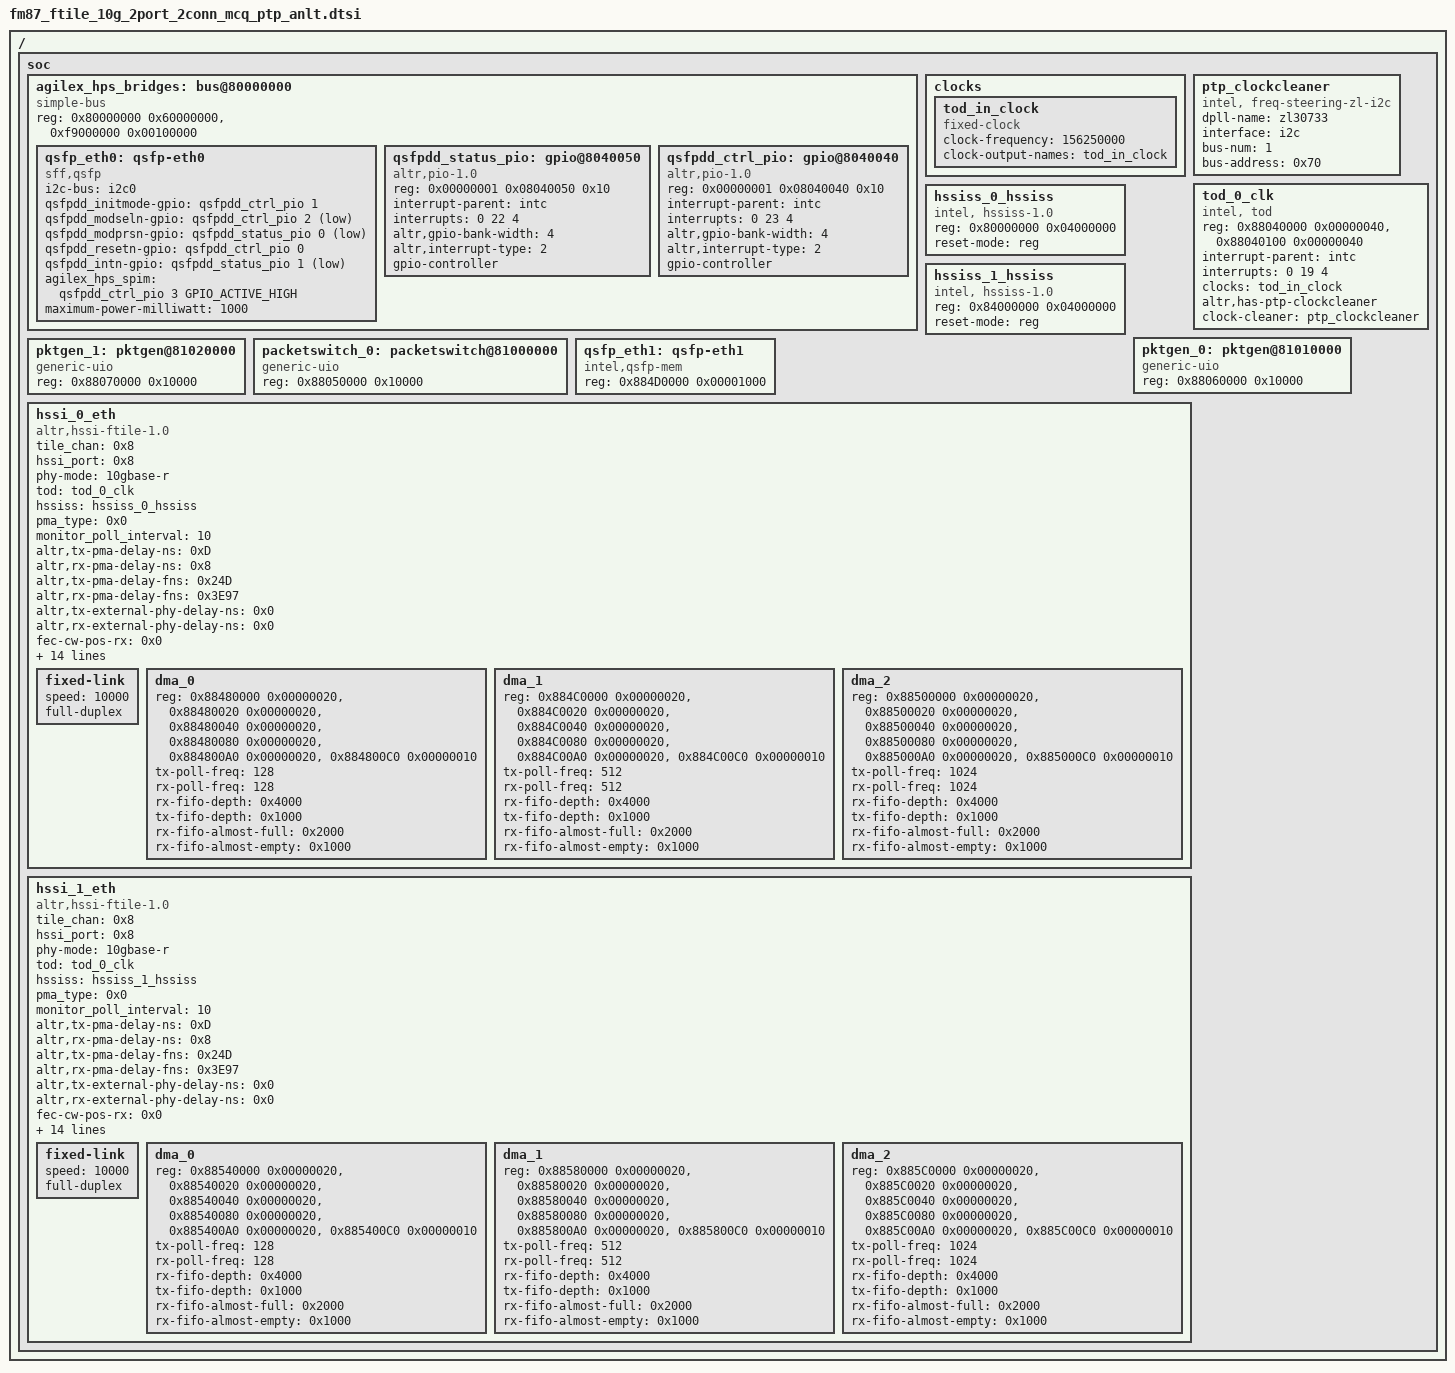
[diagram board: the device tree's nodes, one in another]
// SPDX-License-Identifier: GPL-2.0
/*
 * Copyright(C) 2024, Altera Corporation
 */

/* Add this piece of dtsi fragment as #include "fm87_ftile_25g_ptp.dtsi"
 * in the file socfpga_fm87_ftile_25g_ptp.dts. Compile it in the kernel along with
 * socfpga_agilex.dtsi
 */

/{
	soc {
		agilex_hps_bridges: bus@80000000 {
			compatible = "simple-bus";
			reg = <0x80000000 0x60000000>,
				  <0xf9000000 0x00100000>;
			reg-names = "axi_h2f", "axi_h2f_lw";
			#address-cells = <2>;
			#size-cells = <1>;
			ranges =   <0x00000000 0x00000000 0xf9000000 0x00001000>,
				   <0x00000001 0x00000000 0x80000000 0x04000000>,
				   <0x00000001 0x00000000 0x84000000 0x04000000>,
				   <0x00000001 0x00000000 0x88040000 0x00000040>,
				   <0x00000001 0x00000000 0x88040100 0x00000140>,
				   <0x00000001 0x08040050 0x88040050 0x00000010>,
				   <0x00000001 0x08040040 0x88040040 0x00000010>,
				   <0x00000001 0x00000000 0x88050000 0x00010000>,
				   <0x00000001 0x00000000 0x88060000 0x00010000>,
				   <0x00000001 0x00000000 0x88070000 0x00010000>,
				   <0x00000001 0x00000000 0x88480000 0x00000100>,
				   <0x00000001 0x00000000 0x884C0000 0x00000100>,
				   <0x00000001 0x00000000 0x88500000 0x00000100>,
				   <0x00000001 0x00000000 0x88540000 0x00000100>,
				   <0x00000001 0x00000000 0x88580000 0x00000100>,
				   <0x00000001 0x00000000 0x885C0000 0x00000100>,
				   <0x00000001 0x00000000 0x884D0000 0x00001000>;

			qsfp_eth0: qsfp-eth0 {
				compatible = "sff,qsfp";
				i2c-bus = <&i2c0>;
				qsfpdd_initmode-gpio = <&qsfpdd_ctrl_pio 1 GPIO_ACTIVE_HIGH>;
				qsfpdd_modseln-gpio = <&qsfpdd_ctrl_pio 2 GPIO_ACTIVE_LOW>;
				qsfpdd_modprsn-gpio = <&qsfpdd_status_pio 0 GPIO_ACTIVE_LOW>;
				qsfpdd_resetn-gpio = <&qsfpdd_ctrl_pio 0 GPIO_ACTIVE_HIGH>;
				qsfpdd_intn-gpio = <&qsfpdd_status_pio 1 GPIO_ACTIVE_LOW>;
				agilex_hps_spim = <&qsfpdd_ctrl_pio 3 GPIO_ACTIVE_HIGH>;
				maximum-power-milliwatt = <1000>;
				status = "okay";
			};

			qsfpdd_status_pio: gpio@8040050 {
				compatible = "altr,pio-1.0";
				reg = <0x00000001 0x08040050 0x10>;
				interrupt-parent = <&intc>;
				interrupts = <0 22 4>;
				altr,gpio-bank-width = <4>;
				altr,interrupt-type = <2>;
				#gpio-cells = <2>;
				gpio-controller;
				status = "okay";
			};

			qsfpdd_ctrl_pio: gpio@8040040 {
				compatible = "altr,pio-1.0";
				reg = <0x00000001 0x08040040 0x10>;
				interrupt-parent = <&intc>;
				interrupts = <0 23 4>;
				altr,gpio-bank-width = <4>;
				altr,interrupt-type = <2>;
				#gpio-cells = <2>;
				gpio-controller;
				status = "okay";
			};
		};
		clocks {
			tod_in_clock: tod_in_clock {
				#clock-cells = <0>;
				compatible = "fixed-clock";
				clock-frequency = <156250000>;
				clock-output-names = "tod_in_clock";
			};
		};

		ptp_clockcleaner: ptp_clockcleaner {
			compatible = "intel, freq-steering-zl-i2c";
			dpll-name = "zl30733";
			interface  = "i2c";
			bus-num    = <1>;
			bus-address = <0x70>;
		};

		tod_0_clk: tod_0_clk {
			compatible = "intel, tod";
			reg-names =	"tod_ctrl",
					"pps_ctrl";
			reg = <0x88040000 0x00000040>,
				  <0x88040100 0x00000040>;
			interrupt-parent = <&intc>;
			interrupt-names = "pps_irq";
			interrupts = <0 19 4>;
			clocks = <&tod_in_clock>;
			clock-names = "tod_clock";
			status = "okay";
			altr,has-ptp-clockcleaner;
			clock-cleaner = <&ptp_clockcleaner>;
		};

		hssiss_0_hssiss: hssiss_0_hssiss {
			compatible = "intel, hssiss-1.0";
			reg-names = "sscsr";
			reg = <0x80000000 0x04000000>;
			reset-mode ="reg";
		};
		hssiss_1_hssiss: hssiss_1_hssiss {
			compatible = "intel, hssiss-1.0";
			reg-names = "sscsr";
			reg = <0x84000000 0x04000000>;
			reset-mode ="reg";
		};
		pktgen_0: pktgen@81010000 {
			compatible = "generic-uio";
			reg = <0x88060000 0x10000>;
			reg-names = "pkt_cli";
		};
		pktgen_1: pktgen@81020000 {
			compatible = "generic-uio";
			reg = <0x88070000 0x10000>;
			reg-names = "pkt_cli";
		};
		packetswitch_0: packetswitch@81000000 {
			compatible = "generic-uio";
			reg = <0x88050000 0x10000>;
			reg-names = "packetswitch";
		};
		qsfp_eth1: qsfp-eth1 {
			compatible = "intel,qsfp-mem";
			reg-names = "qsfp-mem-ctrl";
			reg = <0x884D0000 0x00001000>;
			status = "okay";
	    	};
		hssi_0_eth: hssi_0_eth {
			compatible = "altr,hssi-ftile-1.0";
			#address-cells = <1>;
			#size-cells = <1>;
			ranges;
			tile_chan = <0x8>;
			hssi_port = <0x8>;
			phy-mode = "10gbase-r";
			tod = <&tod_0_clk>;
			hssiss = <&hssiss_0_hssiss>;
			pma_type = <0x0>; // FGT - 0x00, FHT = 0x1000
			monitor_poll_interval = <10>;
			altr,tx-pma-delay-ns = <0xD>;
			altr,rx-pma-delay-ns = <0x8>;
			altr,tx-pma-delay-fns = <0x24D>;
			altr,rx-pma-delay-fns = <0x3E97>;
			altr,tx-external-phy-delay-ns = <0x0>;
			altr,rx-external-phy-delay-ns = <0x0>;
			fec-cw-pos-rx = <0x0>;
			fec-type="no-fec";
			qsfp = <&qsfp_eth0>;
			qsfp-lane = <0x0>;
			altr,has-ptp;
			ptp_accu_mode = "Advanced";
			ptp_tx_routing_adj = <24133>; //0.36825 * 65536
			ptp_rx_routing_adj = <13565>; //0.207 * 65536
			status = "okay";
			altr,has-anlt;
			autoneg_enabled = "yes";
			ui-adj-interval = <250>;
			num_channels = <3>;
			interrupt-parent = <&intc>;
			interrupt-names =	"dma0_tx_irq", "dma0_rx_irq",
						"dma1_tx_irq", "dma1_rx_irq",
						"dma2_tx_irq", "dma2_rx_irq";
			interrupts =	<0 40 4>, <0 41 4>,
					<0 38 4>, <0 39 4>,
					<0 36 4>, <0 37 4>;
			fixed-link {
				speed =<10000>;
				full-duplex;
			};
			dma_0 {
				reg-names =	"tx_pref"  ,
						"tx_csr"   ,
						"tx_fifo"  ,
						"rx_pref"  ,
						"rx_csr"   ,
						"rx_fifo";
				reg =	<0x88480000 0x00000020>,
						<0x88480020 0x00000020>,
						<0x88480040 0x00000020>,
						<0x88480080 0x00000020>,
						<0x884800A0 0x00000020>,
						<0x884800C0 0x00000010>;
				tx-poll-freq=<128>;
				rx-poll-freq=<128>;
				rx-fifo-depth = <0x4000>;
				tx-fifo-depth = <0x1000>;
				rx-fifo-almost-full = <0x2000>;
				rx-fifo-almost-empty = <0x1000>;
			};
			dma_1 {
				reg-names =	"tx_pref"  ,
						"tx_csr"   ,
						"tx_fifo"  ,
						"rx_pref"  ,
						"rx_csr"   ,
						"rx_fifo";
				reg =	<0x884C0000 0x00000020>,
						<0x884C0020 0x00000020>,
						<0x884C0040 0x00000020>,
						<0x884C0080 0x00000020>,
						<0x884C00A0 0x00000020>,
						<0x884C00C0 0x00000010>;
				tx-poll-freq=<512>;
				rx-poll-freq=<512>;
				rx-fifo-depth = <0x4000>;
				tx-fifo-depth = <0x1000>;
				rx-fifo-almost-full = <0x2000>;
				rx-fifo-almost-empty = <0x1000>;
			};
			dma_2 {
				reg-names =	"tx_pref"  ,
						"tx_csr"   ,
						"tx_fifo"  ,
						"rx_pref"  ,
						"rx_csr"   ,
						"rx_fifo";
				reg =	<0x88500000 0x00000020>,
						<0x88500020 0x00000020>,
						<0x88500040 0x00000020>,
						<0x88500080 0x00000020>,
						<0x885000A0 0x00000020>,
						<0x885000C0 0x00000010>;
				tx-poll-freq=<1024>;
				rx-poll-freq=<1024>;
				rx-fifo-depth = <0x4000>;
				tx-fifo-depth = <0x1000>;
				rx-fifo-almost-full = <0x2000>;
				rx-fifo-almost-empty = <0x1000>;
			};
		};
		hssi_1_eth: hssi_1_eth {
			compatible = "altr,hssi-ftile-1.0";
			#address-cells = <1>;
			#size-cells = <1>;
			ranges;
			tile_chan = <0x8>;
			hssi_port = <0x8>;
			phy-mode = "10gbase-r";
			tod = <&tod_0_clk>;
			hssiss = <&hssiss_1_hssiss>;
			pma_type = <0x0>; // FGT - 0x00, FHT = 0x1000
			monitor_poll_interval = <10>;
			altr,tx-pma-delay-ns = <0xD>;
			altr,rx-pma-delay-ns = <0x8>;
			altr,tx-pma-delay-fns = <0x24D>;
			altr,rx-pma-delay-fns = <0x3E97>;
			altr,tx-external-phy-delay-ns = <0x0>;
			altr,rx-external-phy-delay-ns = <0x0>;
			fec-cw-pos-rx = <0x0>;
			fec-type="no-fec";
			qsfp = <&qsfp_eth1>;
			qsfp-lane = <0x0>;
			altr,has-ptp;
			ptp_accu_mode = "Advanced";
			ptp_tx_routing_adj = <28737>; // 0.4385 * 65536
			ptp_rx_routing_adj = <20480>; // 0.3125 * 65536
			status = "okay";
			altr,has-anlt;
			autoneg_enabled = "yes";
			ui-adj-interval = <250>;
			num_channels = <3>;
			interrupt-parent = <&intc>;
			interrupt-names =	"dma0_tx_irq", "dma0_rx_irq",
						"dma1_tx_irq", "dma1_rx_irq",
						"dma2_tx_irq", "dma2_rx_irq";
			interrupts =	<0 34 4>, <0 35 4>,
					<0 32 4>, <0 33 4>,
					<0 31 4>, <0 30 4>;
			fixed-link {
				speed =<10000>;
				full-duplex;
			};
			dma_0 {
				reg-names =	"tx_pref"  ,
						"tx_csr"   ,
						"tx_fifo"  ,
						"rx_pref"  ,
						"rx_csr"   ,
						"rx_fifo";
				reg =	<0x88540000 0x00000020>,
						<0x88540020 0x00000020>,
						<0x88540040 0x00000020>,
						<0x88540080 0x00000020>,
						<0x885400A0 0x00000020>,
						<0x885400C0 0x00000010>;
				tx-poll-freq=<128>;
				rx-poll-freq=<128>;
				rx-fifo-depth = <0x4000>;
				tx-fifo-depth = <0x1000>;
				rx-fifo-almost-full = <0x2000>;
				rx-fifo-almost-empty = <0x1000>;
			};
			dma_1 {
				reg-names =	"tx_pref"  ,
						"tx_csr"   ,
						"tx_fifo"  ,
						"rx_pref"  ,
						"rx_csr"   ,
						"rx_fifo";
				reg =	<0x88580000 0x00000020>,
						<0x88580020 0x00000020>,
						<0x88580040 0x00000020>,
						<0x88580080 0x00000020>,
						<0x885800A0 0x00000020>,
						<0x885800C0 0x00000010>;
				tx-poll-freq=<512>;
				rx-poll-freq=<512>;
				rx-fifo-depth = <0x4000>;
				tx-fifo-depth = <0x1000>;
				rx-fifo-almost-full = <0x2000>;
				rx-fifo-almost-empty = <0x1000>;
			};
			dma_2 {
				reg-names =	"tx_pref"  ,
						"tx_csr"   ,
						"tx_fifo"  ,
						"rx_pref"  ,
						"rx_csr"   ,
						"rx_fifo";
				reg =	<0x885C0000 0x00000020>,
						<0x885C0020 0x00000020>,
						<0x885C0040 0x00000020>,
						<0x885C0080 0x00000020>,
						<0x885C00A0 0x00000020>,
						<0x885C00C0 0x00000010>;
				tx-poll-freq=<1024>;
				rx-poll-freq=<1024>;
				rx-fifo-depth = <0x4000>;
				tx-fifo-depth = <0x1000>;
				rx-fifo-almost-full = <0x2000>;
				rx-fifo-almost-empty = <0x1000>;
		    };
		};
	};
};
